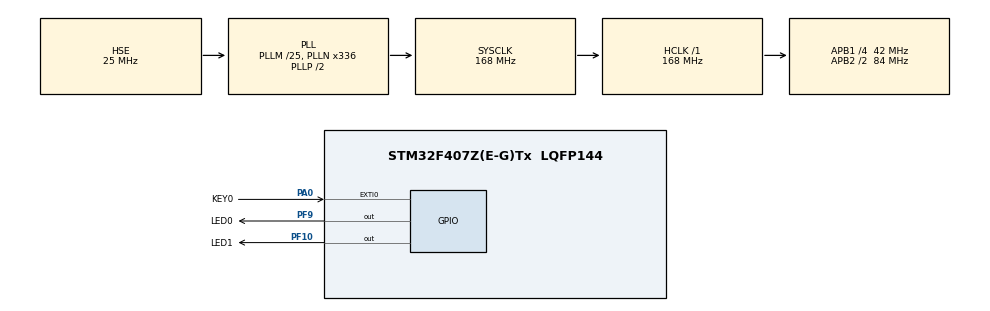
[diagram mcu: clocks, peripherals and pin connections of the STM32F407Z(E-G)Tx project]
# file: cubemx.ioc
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Mcu.Family=STM32F4
Mcu.Name=STM32F407Z(E-G)Tx
Mcu.Package=LQFP144
NVIC.EXTI0_IRQn=true\:0\:0\:false\:false\:true\:true\:true\:true
NVIC.PriorityGroup=NVIC_PRIORITYGROUP_4
PA0-WKUP.GPIO_Label=KEY0
PA0-WKUP.GPIO_PuPd=GPIO_PULLUP
PA0-WKUP.Signal=GPXTI0
PA13.Mode=Serial_Wire
PA13.Signal=SYS_JTMS-SWDIO
PA14.Mode=Serial_Wire
PA14.Signal=SYS_JTCK-SWCLK
PF10.GPIO_Label=LED1
PF10.Signal=GPIO_Output
PF9.GPIO_Label=LED0
PF9.Signal=GPIO_Output
PH0-OSC_IN.Mode=HSE-External-Oscillator
PH0-OSC_IN.Signal=RCC_OSC_IN
PH1-OSC_OUT.Mode=HSE-External-Oscillator
PH1-OSC_OUT.Signal=RCC_OSC_OUT
ProjectManager.HeapSize=0x200
ProjectManager.StackSize=0x400
ProjectManager.TargetToolchain=Makefile
RCC.48MHZClocksFreq_Value=84000000
RCC.AHBFreq_Value=168000000
RCC.APB1CLKDivider=RCC_HCLK_DIV4
RCC.APB1Freq_Value=42000000
RCC.APB1TimFreq_Value=84000000
RCC.APB2CLKDivider=RCC_HCLK_DIV2
RCC.APB2Freq_Value=84000000
RCC.APB2TimFreq_Value=168000000
RCC.CortexFreq_Value=168000000
RCC.HCLKFreq_Value=168000000
RCC.HSE_VALUE=25000000
RCC.HSI_VALUE=16000000
RCC.LSE_VALUE=32768
RCC.PLLM=25
RCC.PLLN=336
RCC.PLLSourceVirtual=RCC_PLLSOURCE_HSE
RCC.SYSCLKFreq_VALUE=168000000
RCC.SYSCLKSource=RCC_SYSCLKSOURCE_PLLCLK
RCC.VCOOutputFreq_Value=336000000
board=custom

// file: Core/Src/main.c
/* USER CODE BEGIN Header */
/**
  ******************************************************************************
  * @file           : main.c
  * @brief          : Main program body
  ******************************************************************************
  * @attention
  *
  * Copyright (c) 2026 STMicroelectronics.
  * All rights reserved.
  *
  * This software is licensed under terms that can be found in the LICENSE file
  * in the root directory of this software component.
  * If no LICENSE file comes with this software, it is provided AS-IS.
  *
  ******************************************************************************
  */
/* USER CODE END Header */
#include "main.h"
#include "gpio.h"

/* USER CODE BEGIN PV */
typedef enum {
    GEAR_P = 0,
    GEAR_R,
    GEAR_N,
    GEAR_D
} GearState;

volatile GearState gear = GEAR_P;   // 当前档位，初始为P档
/* USER CODE END PV */

void SystemClock_Config(void);
/* USER CODE BEGIN PFP */
static void LED_Update(GearState state);
static void DWT_Init(void);
uint32_t DWT_GetCycle(void);        // 供中断回调使用
void Gear_Shift(void);              // 供中断回调调用
/* USER CODE END PFP */

/* USER CODE BEGIN 0 */
/**
 * @brief 根据档位更新LED状态
 * @param state 当前档位
 */
static void LED_Update(GearState state)
{
    switch(state)
    {
        case GEAR_P:
            HAL_GPIO_WritePin(GPIOF, GPIO_PIN_9, GPIO_PIN_SET);   // LED0亮
            HAL_GPIO_WritePin(GPIOF, GPIO_PIN_10, GPIO_PIN_RESET); // LED1灭
            break;
        case GEAR_R:
            HAL_GPIO_WritePin(GPIOF, GPIO_PIN_9, GPIO_PIN_RESET);
            HAL_GPIO_WritePin(GPIOF, GPIO_PIN_10, GPIO_PIN_SET);
            break;
        case GEAR_N:
            HAL_GPIO_WritePin(GPIOF, GPIO_PIN_9, GPIO_PIN_RESET);
            HAL_GPIO_WritePin(GPIOF, GPIO_PIN_10, GPIO_PIN_RESET);
            break;
        case GEAR_D:
            HAL_GPIO_WritePin(GPIOF, GPIO_PIN_9, GPIO_PIN_SET);
            HAL_GPIO_WritePin(GPIOF, GPIO_PIN_10, GPIO_PIN_SET);
            break;
        default:
            break;
    }
}

/**
 * @brief 初始化DWT周期计数器（用于精准延时消抖）
 */
static void DWT_Init(void)
{
    // 使能DWT跟踪单元
    if (!(CoreDebug->DEMCR & CoreDebug_DEMCR_TRCENA_Msk))
    {
        CoreDebug->DEMCR |= CoreDebug_DEMCR_TRCENA_Msk;
    }
    // 复位计数器并使能
    DWT->CYCCNT = 0;
    DWT->CTRL |= DWT_CTRL_CYCCNTENA_Msk;
}

/**
 * @brief 获取当前CPU周期计数
 * @return 当前周期计数值
 */
uint32_t DWT_GetCycle(void)
{
    return DWT->CYCCNT;
}

/**
 * @brief 切换档位（由中断回调调用）
 */
void Gear_Shift(void)
{
    switch(gear)
    {
        case GEAR_P:
            gear = GEAR_R;
            break;
        case GEAR_R:
            gear = GEAR_N;
            break;
        case GEAR_N:
            gear = GEAR_D;
            break;
        case GEAR_D:
            gear = GEAR_P;
            break;
        default:
            gear = GEAR_P;
            break;
    }
    LED_Update(gear);
}
/* USER CODE END 0 */

int main(void)
{

  /* MCU Configuration--------------------------------------------------------*/

  /* Reset of all peripherals, Initializes the Flash interface and the Systick. */
  HAL_Init();

  /* Configure the system clock */
  SystemClock_Config();

  /* Initialize all configured peripherals */
  MX_GPIO_Init();
  /* USER CODE BEGIN 2 */
  // 初始化DWT计数器（用于消抖）
  DWT_Init();
  // 设置初始档位显示（P档）
  LED_Update(gear);
  /* USER CODE END 2 */

  /* Infinite loop */
  while (1)
  {

  }
}

void SystemClock_Config(void)
{
  RCC_OscInitTypeDef RCC_OscInitStruct = {0};
  RCC_ClkInitTypeDef RCC_ClkInitStruct = {0};

  /** Configure the main internal regulator output voltage
  */
  __HAL_RCC_PWR_CLK_ENABLE();
  __HAL_PWR_VOLTAGESCALING_CONFIG(PWR_REGULATOR_VOLTAGE_SCALE1);

  /** Initializes the RCC Oscillators according to the specified parameters
  * in the RCC_OscInitTypeDef structure.
  */
  RCC_OscInitStruct.OscillatorType = RCC_OSCILLATORTYPE_HSE;
  RCC_OscInitStruct.HSEState = RCC_HSE_ON;
  RCC_OscInitStruct.PLL.PLLState = RCC_PLL_ON;
  RCC_OscInitStruct.PLL.PLLSource = RCC_PLLSOURCE_HSE;
  RCC_OscInitStruct.PLL.PLLM = 25;
  RCC_OscInitStruct.PLL.PLLN = 336;
  RCC_OscInitStruct.PLL.PLLP = RCC_PLLP_DIV2;
  RCC_OscInitStruct.PLL.PLLQ = 4;
  if (HAL_RCC_OscConfig(&RCC_OscInitStruct) != HAL_OK)
  {
    Error_Handler();
  }

  /** Initializes the CPU, AHB and APB buses clocks
  */
  RCC_ClkInitStruct.ClockType = RCC_CLOCKTYPE_HCLK|RCC_CLOCKTYPE_SYSCLK
                              |RCC_CLOCKTYPE_PCLK1|RCC_CLOCKTYPE_PCLK2;
  RCC_ClkInitStruct.SYSCLKSource = RCC_SYSCLKSOURCE_PLLCLK;
  RCC_ClkInitStruct.AHBCLKDivider = RCC_SYSCLK_DIV1;
  RCC_ClkInitStruct.APB1CLKDivider = RCC_HCLK_DIV4;
  RCC_ClkInitStruct.APB2CLKDivider = RCC_HCLK_DIV2;

  if (HAL_RCC_ClockConfig(&RCC_ClkInitStruct, FLASH_LATENCY_5) != HAL_OK)
  {
    Error_Handler();
  }
}

void Error_Handler(void)
{
  __disable_irq();
  while (1)
  {
  }
}
